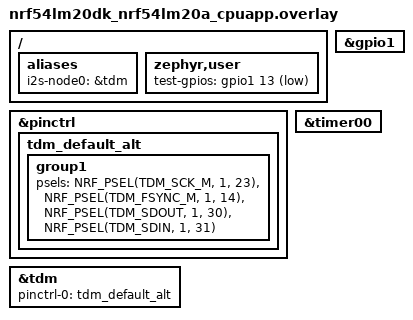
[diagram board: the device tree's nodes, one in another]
/*
 * Copyright (c) 2025 Nordic Semiconductor ASA
 *
 * SPDX-License-Identifier: LicenseRef-Nordic-5-Clause
 */

/* Test requires wire connection:
 *  - I2S_LRCK_M with test-gpios -> P1.14 - P1.13.
 */

/ {
	aliases {
		i2s-node0 = &tdm;
	};
};

/ {
	zephyr,user {
		test-gpios = <&gpio1 13 GPIO_ACTIVE_LOW>;
	};
};

&pinctrl {
	tdm_default_alt: tdm_default_alt {
		group1 {
			psels = <NRF_PSEL(TDM_SCK_M, 1, 23)>,
				<NRF_PSEL(TDM_FSYNC_M, 1, 14)>,
				<NRF_PSEL(TDM_SDOUT, 1, 30)>,
				<NRF_PSEL(TDM_SDIN, 1, 31)>;
		};
	};
};

&gpio1 {
	status = "okay";
};

&tdm {
	status = "okay";
	pinctrl-0 = <&tdm_default_alt>;
	pinctrl-names = "default";
};

&timer00 {
	status = "okay";
};
